# LKS32MC08x register map
Vendor: Linko Ltd.; Series: LKS32MC08x; File version: 1.0
CPU: CM0 r1p0, little endian, MPU, no FPU, 3 interrupt priority bits
Registers are 32-bit, read-write, reset 0x0 unless marked. A register's access mark holds for its fields unless they carry their own. Offsets are from the block's base; [hi:lo] are bit positions; {n}, {i} and the like mark numbered series.

## CAN — CAN registers
Base 0x40013400
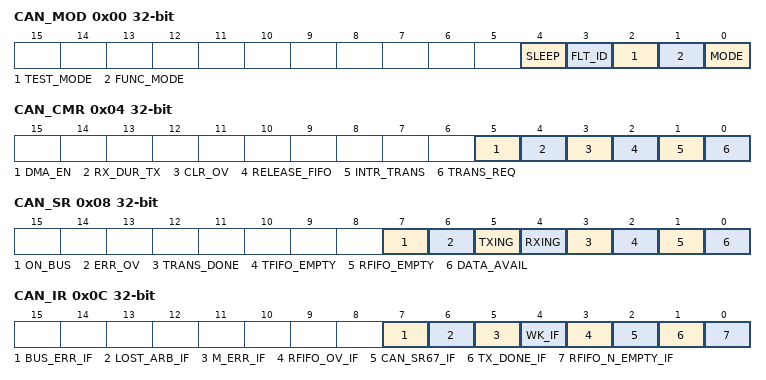
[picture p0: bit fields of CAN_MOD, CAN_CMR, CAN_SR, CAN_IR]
0x00 CAN_MOD — CAN mode register
  [4] SLEEP — Write 1 to enter sleep mode
  [3] FLT_ID — CAN filter ID select
    0=Double short ID; 1=Single (One Single 32bit ID)
  [2] TEST_MODE — Test or function
    0=Function mode; 1=Test mode
  [1] FUNC_MODE — Listen or function
    0=Function mode; 1=Listen mode
  [0] MODE — Reset or function
    0=Function mode; 1=Reset mode
0x04 CAN_CMR wo — CAN command register
  [5] DMA_EN — Write 1 to enable DMA
  [4] RX_DUR_TX — Write 1 to enable Receive data when sending
  [3] CLR_OV — Write 1 to clear overflow IF
  [2] RELEASE_FIFO — Write 1 to release FIFO
  [1] INTR_TRANS — Write 1 to Interrupt unfinished transfer
  [0] TRANS_REQ — Write 1 to generate transfer request
0x08 CAN_SR ro — CAN status register
  [7] ON_BUS — CAN is on Bus or not
    0=OFFBUS (CAN is off bus); 1=ONBUS (CAN is on bus and ready to communicate)
  [6] ERR_OV — Error counter reach CAN_EWL or not
    0=OVER (Error counter reaches CAN_EWL); 1=BELOW (Error counter doesn't reach CAN_EWL)
  [5] TXING — CAN is sending data
    0=IDLE (CAN is not sending any data); 1=BUSY (CAN is sending data)
  [4] RXING — CAN is receiving data
    0=IDLE (CAN is not receiving any data); 1=BUSY (CAN is receiving data)
  [3] TRANS_DONE — Previous transfer is done
    0=NO (Transfer is on-going); 1=YES (Transfer is done)
  [2] TFIFO_EMPTY — Tx FIFO is empty or not
    0=NO (TFIFO is not empty); 1=YES (TFIFO is empty)
  [1] RFIFO_EMPTY — Rx FIFO is empty or not
    0=NO (RFIFO is not empty); 1=YES (RFIFO is empty)
  [0] DATA_AVAIL — There is at least one frame in RFIFO
    0=NO (There is no frame in RFIFO); 1=YES (There is at least one frame in RFIFO)
0x0C CAN_IR ro — CAN interrupt register
  [7] BUS_ERR_IF — Bus error interrupt
  [6] LOST_ARB_IF — Arbitration Lost interrupt
  [5] M_ERR_IF — Entering error status or too many errors occur interrupt
  [4] WK_IF — Wake up from sleep mode interrupt
  [3] RFIFO_OV_IF — RFIFO overflow interrupt
  [2] CAN_SR67_IF — CAN_SR[7:6] changes interrupt
  [1] TX_DONE_IF — Current frame Tx done interrupt
  [0] RFIFO_N_EMPTY_IF — There is new data RFIFO interrupt
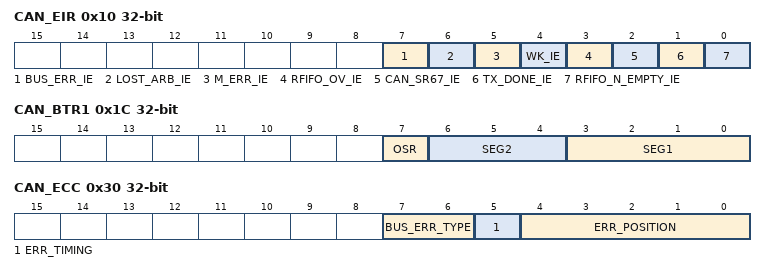
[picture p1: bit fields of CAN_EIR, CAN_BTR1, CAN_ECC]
0x10 CAN_EIR — CAN interrupt control register
  [7] BUS_ERR_IE — Bus error interrupt enable
    0=DISABLED (Bus error interrupt is disabled); 1=ENABLED (Bus error interrupt is enabled)
  [6] LOST_ARB_IE — Arbitration Lost interrupt enable
    0=DISABLED (Arbitration Lost interrupt is disabled); 1=ENABLED (Arbitration Lost interrupt is enabled)
  [5] M_ERR_IE — Entering error status or too many errors occur interrupt enable
    0=DISABLED (Entering error status or too many errors occur interrupt is disabled); 1=ENABLED (Entering error status or too many errors occur interrupt is enabled)
  [4] WK_IE — Wake up from sleep mode interrupt enable
    0=DISABLED (Wake up from sleep mode interrupt is disabled); 1=ENABLED (Wake up from sleep mode interrupt is enabled)
  [3] RFIFO_OV_IE — RFIFO overflow interrupt enable
    0=DISABLED (RFIFO overflow interrupt is disabled); 1=ENABLED (RFIFO overflow interrupt is enabled)
  [2] CAN_SR67_IE — CAN_SR[7:6] changes interrupt enable
    0=DISABLED (CAN_SR[7:6] changes interrupt is disabled); 1=ENABLED (CAN_SR[7:6] changes interrupt is enabled)
  [1] TX_DONE_IE — Current frame Tx done interrupt enable
    0=DISABLED (Current frame Tx done interrupt is disabled); 1=ENABLED (Current frame Tx done interrupt is enabled)
  [0] RFIFO_N_EMPTY_IE — New data in RFIFO interrupt enable
    0=DISABLED (New data in RFIFO interrupt is disabled); 1=ENABLED (New data in RFIFO interrupt is enabled)
0x18 CAN_BTR0 — CAN buadrate 0 register
  [5:0] BUADRATE_0 — TQ = 2*Tclk*(BUADRATE_0+1)
0x1C CAN_BTR1 — CAN buadrate 1 register
  [7] OSR — How many samples per bit
    0=ONE (one sample per bit); 1=THREE (three samples per bit)
  [6:4] SEG2 — Tseg2 = TQ*(4*B6+2*B5+B4+1)
  [3:0] SEG1 — Tseg1 = TQ*(8*B3+4*B2+2*B1+B0+1)
0x2C CAN_ALC — CAN arbitration lost capture register
  [4:0] LOST_ARB — Position where abitration is lost
    0=ID_1 (The first bit of ID); 1=ID_2 (The second bit of ID); 2=ID_3 (The third bit of ID); 3=ID_4 (The fourth bit of ID); 4=ID_5 (The fifth bit of ID); 5=ID_6 (The sixth bit of ID); 6=ID_7 (The seventh bit of ID); 7=ID_8 (The eighth bit of ID); 8=ID_9 (The nighth bit of ID); 9=ID_10 (The tenth bit of ID); 10=ID_11 (The eleventh bit of ID); 11=SRTR; 12=IDE
0x30 CAN_ECC — CAN error code capture register
  [7:6] BUS_ERR_TYPE ro — Bus error type
    0=BIT (Bit error); 1=FORMAT (Format error); 2=FILLER (Filler error); 3=OTHER (Other error)
  [5] ERR_TIMING ro — Error occurs during Tx or Rx
    0=TX (Error occurs during Tx); 1=RX (Error occurs during Rx)
  [4:0] ERR_POSITION ro — Position where error occurs
    2=ID[28:21]; 3=SOF; 4=SRTR; 5=IDE; 6=ID[20:18]; 7=ID[17:13]; 8=CRC; 9=Reserved as 0; 10=Data Field; 11=Data Length Code; 12=RTR; 13=Reserved as 1; 14=ID[4:0]; 15=ID[12:5]; 17=active error flag; 18=Intermission; 19=Tolerate dominant; 22=Passive error flag; 23=Error delimiter; 24=CRC delimiter; 25=Confirm bit; 26=EOF; 27=Confirm delimiter; 28=Overload flag
0x34 CAN_EWLR — CAN error counter threshold register
  [7:0] ERR_TH — Error counter threshold
0x38 CAN_RXERR — CAN Rx error counter register
  [7:0] ERR_CNT — Rx error counter
0x3C CAN_TXERR — CAN Tx error counter register
  [7:0] ERR_CNT — Tx error counter
{0x40+4i} CAN_TXRX{i} (i=0..9) — CAN Tx/Rx register {i}
  [7:0] DATA
0x68 CAN_TXRXA — CAN Tx/Rx register 10
  [7:0] DATA
0x6C CAN_TXRXB — CAN Tx/Rx register 11
  [7:0] DATA
0x70 CAN_TXRXC — CAN Tx/Rx register 12
  [7:0] DATA
0x74 CAN_RMC ro — CAN valid rx data register
  [4:0] FRAME_CNT — Frame counter
0x78 CAN_RBSA — CAN valid rx addr register
  [4:0] FRAME_POINT — Frame Pointer Address
0x7C CAN_CDR — CAN clock division register
  [2:0] CLK_DIV — Clock division ratio
{0x80+4i} CAN_RFIFO{i} (i=0..31) — CAN Rx FIFO {i}
  [7:0] DATA
{0x180+4i} CAN_TFIFO{i} (i=0..12) — CAN Tx FIFO {i}
  [7:0] DATA
